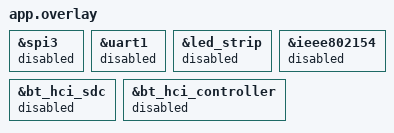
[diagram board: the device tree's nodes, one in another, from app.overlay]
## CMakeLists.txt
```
cmake_minimum_required(VERSION 3.20.0)
find_package(Zephyr REQUIRED HINTS $ENV{ZEPHYR_BASE})
project(koalabyte_t114_display_probe)

target_sources(app PRIVATE
  src/main.c
  ${CMAKE_CURRENT_SOURCE_DIR}/../t114-combined-safe/src/display_power_init.c
  ${CMAKE_CURRENT_SOURCE_DIR}/../t114-combined-safe/src/loading_display.c
)

target_include_directories(app PRIVATE
  ${CMAKE_CURRENT_SOURCE_DIR}/../t114-combined-safe/src
)
```

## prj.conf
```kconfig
# Isolated Heltec T114 display probe for the HT-n5262 UF2 bootloader.
# USB CDC, one-second LED heartbeat and ST7789 only.
# Bluetooth, GNSS, LoRa and unrelated sensors remain disabled.

CONFIG_MAIN_STACK_SIZE=2048
CONFIG_PRINTK=y
CONFIG_LOG=n

CONFIG_BUILD_OUTPUT_UF2=y

CONFIG_GPIO=y
CONFIG_SPI=y
CONFIG_DISPLAY=y
CONFIG_ST7789V=y

CONFIG_SERIAL=y
CONFIG_CONSOLE=y
CONFIG_UART_CONSOLE=y
CONFIG_UART_INTERRUPT_DRIVEN=n
CONFIG_USB_DEVICE_STACK=y
CONFIG_USB_CDC_ACM=y
CONFIG_UART_LINE_CTRL=y

CONFIG_BT=n
CONFIG_GNSS=n
CONFIG_LORA=n
CONFIG_SENSOR=n
CONFIG_IEEE802154=n
CONFIG_LED_STRIP=n
```

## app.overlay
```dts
/* Keep only the ST7789 display bus active for this hardware gate. */

&spi3 {
	status = "disabled";
};

&uart1 {
	status = "disabled";
};

&led_strip {
	status = "disabled";
};

&ieee802154 {
	status = "disabled";
};

&bt_hci_sdc {
	status = "disabled";
};

&bt_hci_controller {
	status = "disabled";
};
```

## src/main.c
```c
#include "loading_display.h"

#include <zephyr/device.h>
#include <zephyr/devicetree.h>
#include <zephyr/drivers/gpio.h>
#include <zephyr/kernel.h>
#include <zephyr/sys/printk.h>
#include <zephyr/usb/usb_device.h>

#include <errno.h>
#include <stdbool.h>
#include <stdint.h>

#define LED0_NODE DT_ALIAS(led0)

#if !DT_NODE_HAS_STATUS(LED0_NODE, okay)
#error "Heltec T114 display probe requires the led0 alias"
#endif

static const struct gpio_dt_spec status_led =
    GPIO_DT_SPEC_GET(LED0_NODE, gpios);

int main(void)
{
    int led_rc;
    int usb_rc;
    bool display_ready;
    bool led_on = false;
    uint32_t heartbeat = 0;

    led_rc = gpio_is_ready_dt(&status_led)
                 ? gpio_pin_configure_dt(&status_led, GPIO_OUTPUT_INACTIVE)
                 : -ENODEV;

    usb_rc = usb_enable(NULL);
    k_sleep(K_MSEC(1200));

    display_ready = loading_display_init();

    printk("{\"type\":\"t114_display_probe\",\"stage\":\"started\","
           "\"profile\":\"usb_led_st7789_only\","
           "\"display\":true,\"bluetooth\":false,"
           "\"gnss\":false,\"lora\":false,"
           "\"led_rc\":%d,\"usb_rc\":%d,"
           "\"display_ready\":%s}\n",
           led_rc, usb_rc, display_ready ? "true" : "false");

    while (true) {
        if (led_rc == 0) {
            led_on = !led_on;
            (void)gpio_pin_set_dt(&status_led, led_on ? 1 : 0);
        }

        printk("{\"type\":\"t114_display_probe\","
               "\"stage\":\"heartbeat\",\"count\":%u,"
               "\"uptime_ms\":%lld,\"display_ready\":%s}\n",
               heartbeat++, (long long)k_uptime_get(),
               loading_display_ready() ? "true" : "false");

        k_sleep(K_SECONDS(1));
    }

    return 0;
}
```
